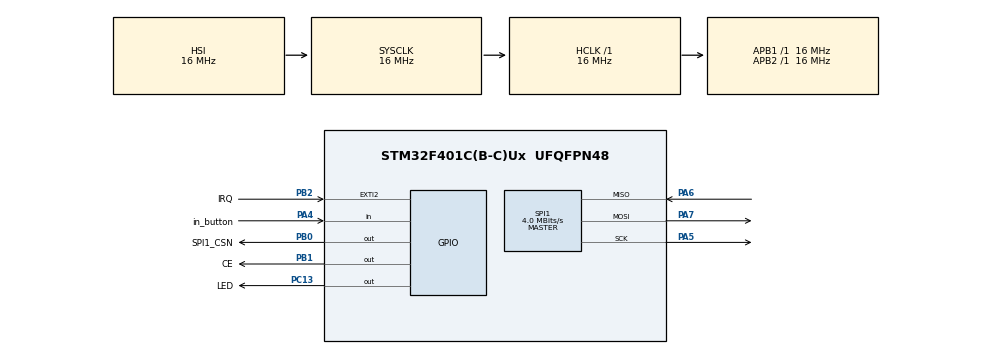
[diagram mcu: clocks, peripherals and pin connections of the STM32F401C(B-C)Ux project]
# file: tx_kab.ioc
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Mcu.Family=STM32F4
Mcu.Name=STM32F401C(B-C)Ux
Mcu.Package=UFQFPN48
NVIC.EXTI2_IRQn=true\:0\:0\:false\:false\:true\:true\:true\:true
NVIC.PriorityGroup=NVIC_PRIORITYGROUP_4
NVIC.TIM4_IRQn=true\:0\:0\:false\:false\:true\:true\:true\:true
PA4.GPIO_Label=in_button
PA4.GPIO_PuPd=GPIO_PULLDOWN
PA4.Signal=GPIO_Input
PA5.Mode=Full_Duplex_Master
PA5.Signal=SPI1_SCK
PA6.Mode=Full_Duplex_Master
PA6.Signal=SPI1_MISO
PA7.Mode=Full_Duplex_Master
PA7.Signal=SPI1_MOSI
PB0.GPIO_Label=SPI1_CSN
PB0.GPIO_Speed=GPIO_SPEED_FREQ_HIGH
PB0.PinState=GPIO_PIN_SET
PB0.Signal=GPIO_Output
PB1.GPIO_Label=CE
PB1.GPIO_Speed=GPIO_SPEED_FREQ_HIGH
PB1.Signal=GPIO_Output
PB2.GPIO_Label=IRQ
PB2.GPIO_ModeDefaultEXTI=GPIO_MODE_IT_FALLING
PB2.Signal=GPXTI2
PC13-ANTI_TAMP.GPIO_Label=LED
PC13-ANTI_TAMP.Signal=GPIO_Output
ProjectManager.HeapSize=0x200
ProjectManager.StackSize=0x400
ProjectManager.TargetToolchain=STM32CubeIDE
RCC.AHBFreq_Value=16000000
RCC.APB1Freq_Value=16000000
RCC.APB2Freq_Value=16000000
RCC.CortexFreq_Value=16000000
RCC.HSE_VALUE=25000000
RCC.HSI_VALUE=16000000
RCC.LSE_VALUE=32768
RCC.SYSCLKFreq_VALUE=16000000
RCC.VCOOutputFreq_Value=192000000
SPI1.BaudRatePrescaler=SPI_BAUDRATEPRESCALER_4
SPI1.CalculateBaudRate=4.0 MBits/s
SPI1.DataSize=SPI_DATASIZE_8BIT
SPI1.Direction=SPI_DIRECTION_2LINES
SPI1.Mode=SPI_MODE_MASTER
SPI1.VirtualType=VM_MASTER
TIM4.Period=500-1
TIM4.Prescaler=16000-1
VP_TIM4_VS_ClockSourceINT.Mode=Internal
board=custom

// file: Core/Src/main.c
/* USER CODE BEGIN Header */
/**
  ******************************************************************************
  * @file           : main.c
  * @brief          : Main program body
  ******************************************************************************
  * @attention
  *
  * Copyright (c) 2023 STMicroelectronics.
  * All rights reserved.
  *
  * This software is licensed under terms that can be found in the LICENSE file
  * in the root directory of this software component.
  * If no LICENSE file comes with this software, it is provided AS-IS.
  *
  ******************************************************************************
  */
/* USER CODE END Header */
#include "main.h"
#include "spi.h"
#include "tim.h"
#include "gpio.h"

/* USER CODE BEGIN Includes */
#include "nrf24l01p.h"
/* USER CODE END Includes */

void SystemClock_Config(void);
/* USER CODE BEGIN PFP */
void HAL_GPIO_EXTI_Callback(uint16_t GPIO_Pin);

/* USER CODE END PFP */

/* USER CODE BEGIN 0 */
uint8_t tx_data[NRF24L01P_PAYLOAD_LENGTH] = {1, 0};
uint8_t pipe_addr[NRF24L01P_PIPE_ADDRESS_WIDTH] = {0xA0, 0x2E, 0xA4, 0xB4, 0x6F};
/* USER CODE END 0 */

int main(void)
{

  /* MCU Configuration--------------------------------------------------------*/

  /* Reset of all peripherals, Initializes the Flash interface and the Systick. */
  HAL_Init();

  /* Configure the system clock */
  SystemClock_Config();

  /* Initialize all configured peripherals */
  MX_GPIO_Init();
  MX_SPI1_Init();
  MX_TIM4_Init();
  /* USER CODE BEGIN 2 */
  nrf24l01p_tx_init(2500, _1Mbps, pipe_addr);
  HAL_TIM_Base_Start_IT(&htim4);
  /* USER CODE END 2 */

  /* Infinite loop */
  while (1)
  {

  }
}

void SystemClock_Config(void)
{
  RCC_OscInitTypeDef RCC_OscInitStruct = {0};
  RCC_ClkInitTypeDef RCC_ClkInitStruct = {0};

  /** Configure the main internal regulator output voltage
  */
  __HAL_RCC_PWR_CLK_ENABLE();
  __HAL_PWR_VOLTAGESCALING_CONFIG(PWR_REGULATOR_VOLTAGE_SCALE2);

  /** Initializes the RCC Oscillators according to the specified parameters
  * in the RCC_OscInitTypeDef structure.
  */
  RCC_OscInitStruct.OscillatorType = RCC_OSCILLATORTYPE_HSI;
  RCC_OscInitStruct.HSIState = RCC_HSI_ON;
  RCC_OscInitStruct.HSICalibrationValue = RCC_HSICALIBRATION_DEFAULT;
  RCC_OscInitStruct.PLL.PLLState = RCC_PLL_NONE;
  if (HAL_RCC_OscConfig(&RCC_OscInitStruct) != HAL_OK)
  {
    Error_Handler();
  }

  /** Initializes the CPU, AHB and APB buses clocks
  */
  RCC_ClkInitStruct.ClockType = RCC_CLOCKTYPE_HCLK|RCC_CLOCKTYPE_SYSCLK
                              |RCC_CLOCKTYPE_PCLK1|RCC_CLOCKTYPE_PCLK2;
  RCC_ClkInitStruct.SYSCLKSource = RCC_SYSCLKSOURCE_HSI;
  RCC_ClkInitStruct.AHBCLKDivider = RCC_SYSCLK_DIV1;
  RCC_ClkInitStruct.APB1CLKDivider = RCC_HCLK_DIV1;
  RCC_ClkInitStruct.APB2CLKDivider = RCC_HCLK_DIV1;

  if (HAL_RCC_ClockConfig(&RCC_ClkInitStruct, FLASH_LATENCY_0) != HAL_OK)
  {
    Error_Handler();
  }
}

/* USER CODE BEGIN 4 */

void HAL_GPIO_EXTI_Callback(uint16_t GPIO_Pin)
{
	if(GPIO_Pin == NRF24L01P_IRQ_PIN_NUMBER)
		nrf24l01p_tx_irq(); // clear interrupt flag
}

/* USER CODE END 4 */

void Error_Handler(void)
{
  __disable_irq();
  while (1)
  {
  }
}
